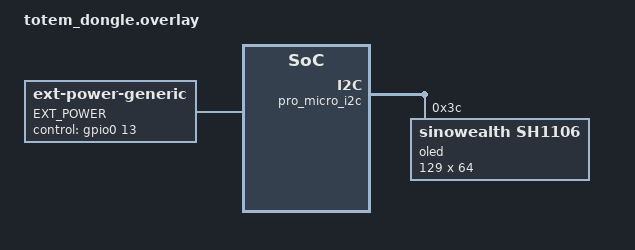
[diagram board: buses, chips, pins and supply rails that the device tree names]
/*
 * Copyright (c) 2022 The ZMK Contributors
 *
 * SPDX-License-Identifier: MIT
 */

#include "totem.dtsi"

/ {
    chosen {
        zmk,kscan = &mock_kscan;
        zephyr,display = &oled;
    };

    mock_kscan: kscan_1 {
        compatible = "zmk,kscan-mock";
        columns = <0>;
        rows = <0>;
        events = <0>;
    };


    ext-power {
        compatible = "zmk,ext-power-generic";
        label = "EXT_POWER";
        control-gpios = <&gpio0 13 GPIO_ACTIVE_HIGH>;
        init-delay-ms = <50>;
    };

    kscan0: kscan_0 {
        wakeup-source;
    };

};

&pro_micro_i2c {
    status = "okay";
    oled: sh1106@3c {
        compatible = "sinowealth,sh1106";
        reg = <0x3c>;
        width = <129>;
        height = <64>;
        segment-offset = <1>;
        page-offset = <0>;
        display-offset = <0>;
        multiplex-ratio = <63>;
        segment-remap;
        com-invdir;
        inversion-on;
        prechargep = <0x22>;
    };
};
